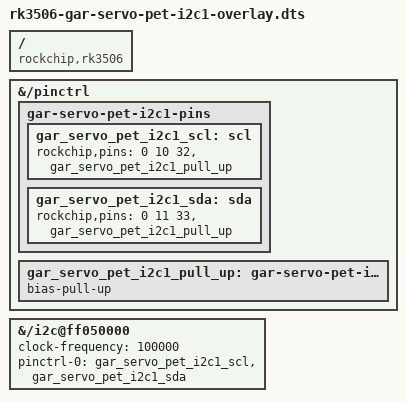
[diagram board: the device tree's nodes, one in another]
/dts-v1/;
/plugin/;

/ {
	compatible = "rockchip,rk3506";

	fragment@0 {
		target-path = "/pinctrl";

		__overlay__ {
			gar-servo-pet-i2c1-pins {
				gar_servo_pet_i2c1_scl: scl {
					rockchip,pins = <0 10 32 &gar_servo_pet_i2c1_pull_up>;
				};

				gar_servo_pet_i2c1_sda: sda {
					rockchip,pins = <0 11 33 &gar_servo_pet_i2c1_pull_up>;
				};
			};

			gar_servo_pet_i2c1_pull_up: gar-servo-pet-i2c1-pull-up {
				bias-pull-up;
			};
		};
	};

	fragment@1 {
		target-path = "/i2c@ff050000";

		__overlay__ {
			status = "okay";
			clock-frequency = <100000>;
			pinctrl-names = "default";
			pinctrl-0 = <&gar_servo_pet_i2c1_scl &gar_servo_pet_i2c1_sda>;
		};
	};
};
